# A31G324 register map
Vendor: ABOV Semiconductor Co., Ltd.; Series: A31G324; File version: 1.0
CPU: CM0PLUS r0p1, little endian, no MPU, no FPU, VTOR, 2 interrupt priority bits
Registers are 32-bit, read-write, reset 0x0 unless marked. A register's access mark holds for its fields unless they carry their own. Offsets are from the block's base; [hi:lo] are bit positions; {n}, {i} and the like mark numbered series.

## DMAC0 — DIRECT MEMORY ACCESS CONTROLLER
Base 0x40000400
Same registers: DMAC1 0x40000410, DMAC2 0x40000420, DMAC3 0x40000430
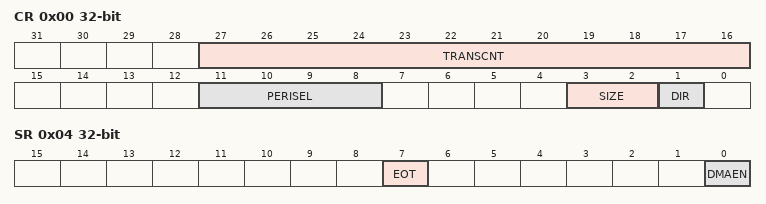
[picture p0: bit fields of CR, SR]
0x00 CR — DMA Controller Configuration Register
  [27:16] TRANSCNT — Number of DMA transfer remained Required transfer number should be written before enable DMA transfer. 0 : DMA transfer is done. N : N transfers are remained.
  [11:8] PERISEL — Peripheral selction N : Associated peripheral selection. Refer to DMA Peripheral connection table
  [3:2] SIZE — Bus transfer size. 00: DMA transfer is byte size transfer 01: DMA transfer is half word size transfer 10: DMA transfer is word size transfer 11: Reserved
  [1] DIR — Select transfer direction. 0: Transfer direction is from memory to peripheral. (TX) 1: Transfer direction is from peripheral to memory. (RX)
0x04 SR — DMA Controller Status Register
  [7] EOT — End of transfer. 0: Data to be transferred is existing. TRANSCNT shows non zero value 1: All data is transferred. TRANSCNT shows now 0
  [0] DMAEN — DMA Enable 0: DMA is in stop or hold state 1: DMA is running or enabled
0x08 PAR — DMA Channel n Peripheral Address
  [15:0] PAR — Target Peripheral address of transmit buffer or receive buffer. Address is fixed address when each transfer is done. If DIR is "0" this address is destination address of data transfer. If DIR is "1", this address is source address of data transfer.
0x0C MAR reset 0x20000000 — DMA Channel n Memory Address
  [31:0] MAR — Target memory address of data transfer. Address is automatically incremented according to SIZE bits when each transfer is done. If DIR is "0" this address is source address of data transfer. If DIR is "1", this address is destination address of data transfer.

## EBI — Static memory controller
Base 0x40006200
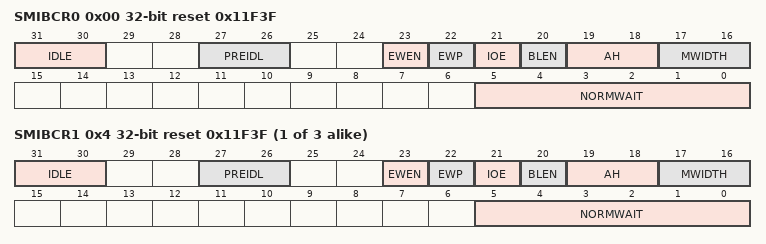
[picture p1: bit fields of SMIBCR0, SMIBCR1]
0x00 SMIBCR0 reset 0x11F3F — Memory area configuration Register 0
  [31:30] IDLE — Insert IDLE cycle at memory access time
  [27:26] PREIDL — Changing falling timing of RD and nUWR/nLWR
  [23] EWEN — Ignore/Enable external input nWAIT
  [22] EWP — nWAIT polarity is active low/high
  [21] IOE — 0: Separated muxed Address/Data access 1 : Enable muxed Address/Data access
  [20] BLEN — Disable/Enable byte lane selection in case of 8bit memory organization
  [19:18] AH — When accessing A/D mux I/O area, "AH" represents the time (the number of clock cycle) while the address is valid. Address keeps the value for "AH + 1" clock (HCLK) cycle.
  [17:16] MWIDTH — External memory bus is 8bit/16bit width
  [5:0] NORMWAIT — It represents wait value to be used for memory read/write operation. 1-64 wait is supported and wait value is NORMWAIT+1.
{0x0+4i} SMIBCR{i} reset 0x11F3F (reset mask 0xCCFF001F) (i=1..3) — Memory area configuration Register {i}
  [31:30] IDLE — Insert IDLE cycle at memory access time
  [27:26] PREIDL — Changing falling timing of RD and nUWR/nLWR
  [23] EWEN — Ignore/Enable external input nWAIT
  [22] EWP — nWAIT polarity is active low/high
  [21] IOE — 0: Separated muxed Address/Data access 1: Enable muxed Address/Data access
  [20] BLEN — Disable/Enable byte lane selection in case of 8bit memory organization
  [19:18] AH — When accessing A/D mux I/O area, "AH" represents the time (the number of clock cycle) while the address is valid. Address keeps the value for "AH + 1" clock (HCLK) cycle.
  [17:16] MWIDTH — External memory bus is 8bit/16bit width
  [5:0] NORMWAIT — It represents wait value to be used for memory read/write operation. 1-64 wait is supported and wait value is NORMWAIT+1.

## WDT — WATCH-DOG TIMER
Base 0x40001A00
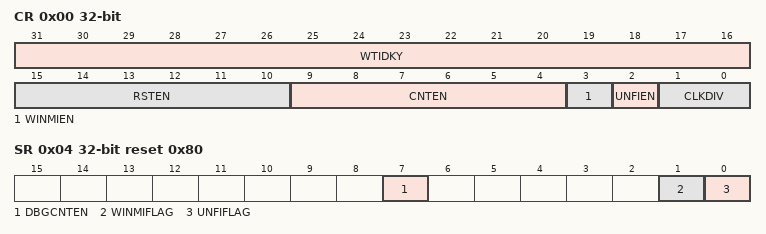
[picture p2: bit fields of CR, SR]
0x00 CR — Watch-dog Timer Control Register
  [31:16] WTIDKY wo — Write Identification Key. On writes, write 0x5A69 to these bits, otherwise the write is ignored.
  [15:10] RSTEN — Watch-dog Timer Reset Enable bits
  [9:4] CNTEN — Watch-dog Timer Counter Enable bits
  [3] WINMIEN — Watch-dog Timer Window Match Interrupt Enable bit
  [2] UNFIEN — Watch-dog Timer Underflow Interrupt Enable bit
  [1:0] CLKDIV — Watch-dog Timer Clock Divider bits, The clock which is selected by PPCLKSR[0]
0x04 SR reset 0x80 — Watch-dog Timer Status Register
  [7] DBGCNTEN — Watch-dog Timer Counter Enable bit. When the core is halted in the debug mode. Note: This bit is cleared to "0b" only by POR reset.
    0=RUN_CORE_HALTED (The watch-dog timer counter continues even if the core is halted.); 1=STOP_CORE_HALTED (The watch-dog timer counter is stopped when the core is halted.)
  [1] WINMIFLAG — Watch-dog Timer Window Match Interrupt Flag bit
    0=WDT_WDM_IF_CLR (No request occurred); 1=WDT_WDM_IF_SET (Request occurred, This bit is cleared to '0' when write '1'.)
  [0] UNFIFLAG — Watch-dog Timer Underflow Interrupt Flag bit
    0=WDT_UDF_IF_CLR (No request occurred); 1=WDT_UDF_IF_SET (Request occurred, This bit is cleared to '0' when write '1'.)
0x08 DR reset 0xFFF — Watch-dog Timer Data Register
  [23:0] DATA — Watch-dog Timer Data bits. The range is 0x000000 to 0xFFFFFF.
0x0C CNT ro reset 0xFFF — Watch-dog Timer Counter Register
  [23:0] CNT — Watch-dog Timer Counter bits.
0x10 WINDR reset 0x1FFF — Watch-dog Timer Window Data Register (Note: Once any value is written to this window data register, the register can't be changed until a system reset.)
  [23:0] WDATA — Watch-dog Timer Window Data bits. The range is 0x000000 to 0xFFFFFF.
0x14 CNTR wo — Watch-dog Timer Counter Reload Register
  [7:0] CNTR — Watch-dog Timer Counter Reload bits.
    106=RELOAD_WDTDR (Reload the WDTDR value to watch-dog timer counter and re-start. (Automatically cleared to "0x00" after operation)); 0=UNLOAD_WDTDR (No effect)
